# K1921VG7T register map
Vendor: NIIET; Series: K1921VKx; File version: 1.0
CPU: CM4 r0p1, Endian.LITTLE endian, MPU, FPU
Registers are 32-bit, read-write, reset 0x0 unless marked. A register's access mark holds for its fields unless they carry their own. Offsets are from the block's base; [hi:lo] are bit positions; lines under a group give offsets from that group; {n}, {i} and the like mark numbered series; 'fields as' and 'values as' point back to an identical list.

## RCU — Reset and clock unit
Base 0x50004000
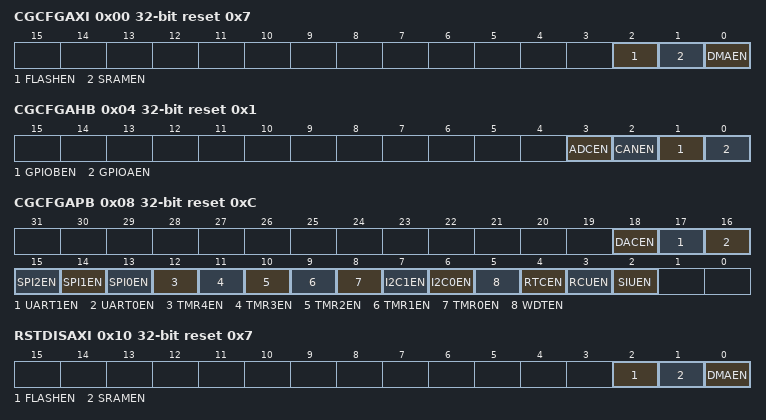
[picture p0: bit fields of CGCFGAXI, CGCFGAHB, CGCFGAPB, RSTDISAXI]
0x00 CGCFGAXI reset 0x7 — Clockgate Config AHB register
  [2] FLASHEN — Boot flash AXI and APB clock enable
  [1] SRAMEN — SRAM module clock enable
  [0] DMAEN — DMA AXI and APB clock enable
0x04 CGCFGAHB reset 0x1 — Clockgate Config AHB register
  [3] ADCEN, [2] CANEN, [1] GPIOBEN, [0] GPIOAEN
0x08 CGCFGAPB reset 0xC — Clockgate Config APB register
  [18] DACEN
  [17] UART1EN
  [16] UART0EN
  [15] SPI2EN
  [14] SPI1EN
  [13] SPI0EN
  [12] TMR4EN — TMR16_2 clock enable
  [11] TMR3EN — TMR16_1 clock enable
  [10] TMR2EN — TMR16_0 clock enable
  [9] TMR1EN — TMR32_1 clock enable
  [8] TMR0EN — TMR32_0 clock enable
  [7] I2C1EN
  [6] I2C0EN
  [5] WDTEN
  [4] RTCEN
  [3] RCUEN ro
  [2] SIUEN ro
0x10 RSTDISAXI reset 0x7 — Reset Disable AXI register
  [2] FLASHEN ro — Boot flash reset disable
  [1] SRAMEN — SRAM module reset disable
  [0] DMAEN — DMA reset disable
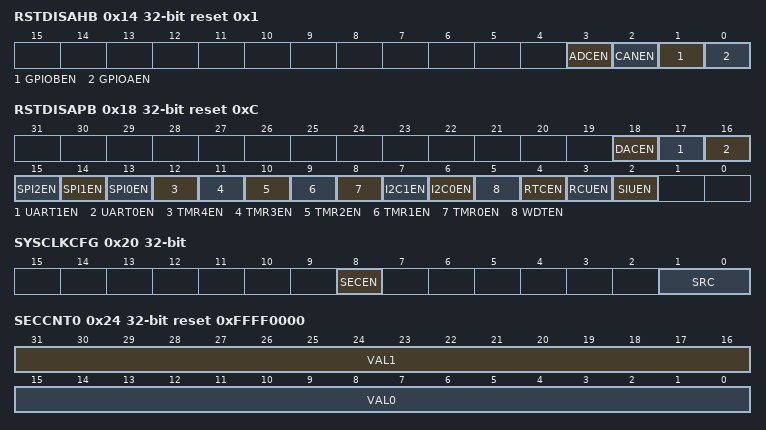
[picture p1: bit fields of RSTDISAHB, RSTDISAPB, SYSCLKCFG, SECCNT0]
0x14 RSTDISAHB reset 0x1 — Reset Disable AHB register
  [3] ADCEN, [2] CANEN, [1] GPIOBEN, [0] GPIOAEN
0x18 RSTDISAPB reset 0xC — Reset Disable APB register
  [18] DACEN
  [17] UART1EN
  [16] UART0EN
  [15] SPI2EN
  [14] SPI1EN
  [13] SPI0EN
  [12] TMR4EN — TMR16_2 clock enable
  [11] TMR3EN — TMR16_1 reset disable
  [10] TMR2EN — TMR16_0 reset disable
  [9] TMR1EN — TMR32_1 reset disable
  [8] TMR0EN — TMR32_0 reset disable
  [7] I2C1EN
  [6] I2C0EN
  [5] WDTEN
  [4] RTCEN
  [3] RCUEN ro
  [2] SIUEN ro
0x20 SYSCLKCFG — System clock configuration register
  [8] SECEN
  [1:0] SRC — System clock source
    0=REFCLK (HSI 1MHz if CPE=0 or HSE(XTALL) if CPE=1); 1=SRCCLK (HSE(XTALL) if CPE=0 or HSI 1MHz if CPE=1); 2=SYSPLL0CLK (Clock from PLL OUT[0]); 3=EXTCLK (external CLK from gpio pin)
0x24 SECCNT0 reset 0xFFFF0000 — Security counter configuration 0 register
  [31:16] VAL1, [15:0] VAL0 ro
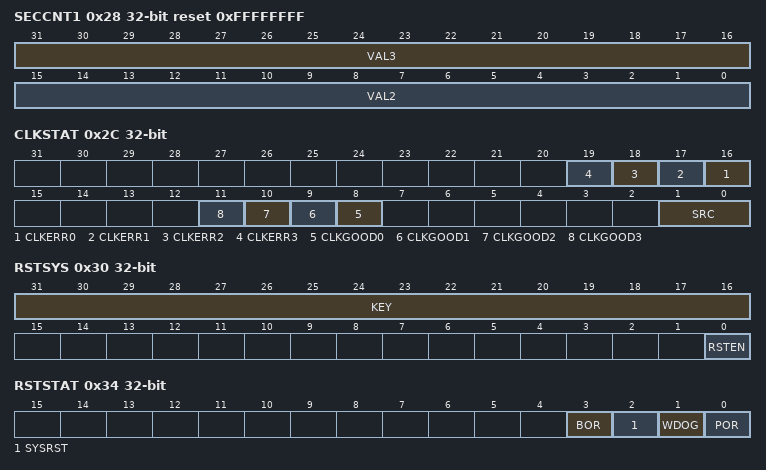
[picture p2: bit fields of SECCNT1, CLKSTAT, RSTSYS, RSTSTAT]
0x28 SECCNT1 reset 0xFFFFFFFF — Security counter configuration 1 register
  [31:16] VAL3, [15:0] VAL2
0x2C CLKSTAT ro — System clock status register
  [n+16] CLKERR{n} (n=0..3)
  [n+8] CLKGOOD{n} (n=0..3)
  [1:0] SRC — REFCLK:0:HSI 1MHz if CPE=0 or HSE(XTALL) if CPE=1;SRCCLK:1:HSE(XTALL) if CPE=0 or HSI 1MHz if CPE=1;SYSPLL0CLK:2: Clock from PLL OUT[0];EXTCLK:3: external CLK from gpio pin;
0x30 RSTSYS wo — System Reset Register
  [31:16] KEY — KEY 'A55A' in hexadecimal for unblocking
    0xA55A=VALID (Value that lead to chip reset if RSTEN = 1); 0=DUMMY_0 (Example value that prevents reset); 1=DUMMY_1 (Example value that prevents reset)
  [0] RSTEN — Reset enable
0x34 RSTSTAT — Reset Status Register
  [3] BOR — Brown-out reset status
  [2] SYSRST — System Reset Status
  [1] WDOG — WatchDog Reset status
  [0] POR — PowerOn Reset status
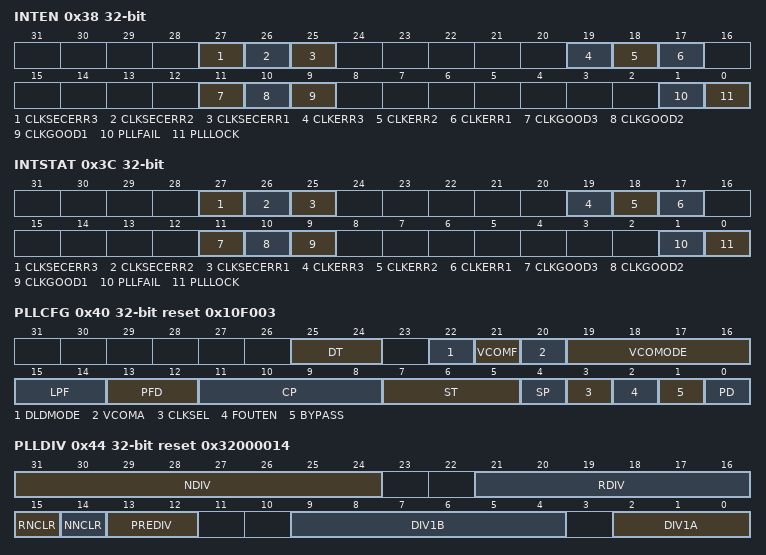
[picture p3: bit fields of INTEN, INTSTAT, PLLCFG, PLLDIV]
0x38 INTEN — Interrupt enable reigster
  [27] CLKSECERR3
  [26] CLKSECERR2
  [25] CLKSECERR1
  [19] CLKERR3
  [18] CLKERR2
  [17] CLKERR1
  [11] CLKGOOD3
  [10] CLKGOOD2
  [9] CLKGOOD1
  [1] PLLFAIL — Enable PLL fail to lock interrupt
  [0] PLLLOCK — Enable PLL lock interrupt
0x3C INTSTAT — Interrupt status register
  [27] CLKSECERR3
  [26] CLKSECERR2
  [25] CLKSECERR1
  [19] CLKERR3
  [18] CLKERR2
  [17] CLKERR1
  [11] CLKGOOD3
  [10] CLKGOOD2
  [9] CLKGOOD1
  [1] PLLFAIL — PLL lock signal drop occured
  [0] PLLLOCK — PLL lock signal raise occured
0x40 PLLCFG reset 0x10F003 — PLL Configuration Register
  [25:24] DT — fractional noise randomization mode
  [22] DLDMODE — Frequency detector delay
  [21] VCOMF — Ajust lower range of GUN
  [20] VCOMA — Ajust amplitude of GUN
  [19:16] VCOMODE — Subband selection signal
  [15:14] LPF — Loop filter band
  [13:12] PFD — Mode of current switch
  [11:8] CP — Output current of current switch
  [7:5] ST — Sggma-delta modulator mode
  [4] SP — Song-Park mode
  [3] CLKSEL — PLL reference clock source select
    0=HSE (external oscilator clock > 10 Mhz); 1=EXTCLK (external clock from GPIO pin)
  [2] FOUTEN — Fout enable
  [1] BYPASS — Bypass enable
  [0] PD — Powerdown enable
0x44 PLLDIV reset 0x32000014 — PLL DIV Configuration Register
  [31:24] NDIV — Integer part of divider (divide pre-divisor result by NDIV)
  [21:16] RDIV — R-divider coefficient (divide Fin by (RDIV + 1))
  [15] RNCLR — R-divider enable
  [14] NNCLR — N-divider enable
  [13:12] PREDIV — Pre-divisor coefficient. PREDIV = 0 | 1 | 2 | 3 -> divide Fvco by 1 | 1 | 2 | 3
  [9:4] DIV1B — Divider 1B (divide divider 1A result by (DIV1B + 1))
  [2:0] DIV1A — Divider 1A (divide pre-divisor result by (DIV1A + 1))
0x48 PLLFRAC — PLL FRAC Configuration Register
  [23:0] FRAC — numerator of fractional part
0x4C PLLMOD reset 0xFFFFFF — PLL MOD Configuration Register
  [23:0] MOD — denominator of fractional part
{0x50+4i} UARTCFG[{i}] (i=0..1) group
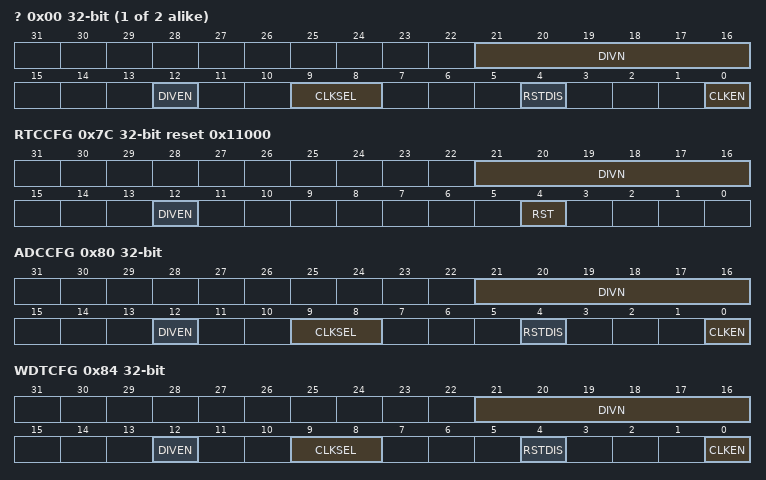
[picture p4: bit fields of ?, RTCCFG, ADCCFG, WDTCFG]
  0x00 ? — UART Clock and Reset Configuration Register
    [21:16] DIVN — Divider coefficient
    [12] DIVEN — Enable division by (2 * (DIVN + 1))
    [9:8] CLKSEL — Clock source select
      0=REFCLK (HSI 4MHz if CPE=0 or HSE(XTALL) if CPE=1); 1=SRCCLK (HSE(XTALL) if CPE=0 or HSI 4MHz if CPE=1); 2=SYSPLL0CLK (Clock from PLL OUT[0]); 3=EXTCLK (external CLK from gpio pin)
    [4] RSTDIS — Reset disable
    [0] CLKEN — Clock enable
{0x70+4i} SPICFG[{i}] (i=0..2) group
  0x00 ? — SPI Clock and Reset Configuration Register
    [21:16] DIVN — Divider coefficient
    [12] DIVEN — Enable divider by (2 * (DIVN + 1))
    [9:8] CLKSEL — Clock source select
      values as UARTCFG[0].?.CLKSEL
    [4] RSTDIS — Reset disable
    [0] CLKEN — Clock enable
0x7C RTCCFG reset 0x11000 — RTC APB clock divider and reset
  [21:16] DIVN — APB clock divider coefficient
  [12] DIVEN — Enable APB clock division by (2 * (DIVN + 1))
  [4] RST — Reset active High
0x80 ADCCFG — ADC Clock and Reset Configuration Register
  fields as UARTCFG[0].?
0x84 WDTCFG — WatchDog Configuration Register
  fields as UARTCFG[0].?
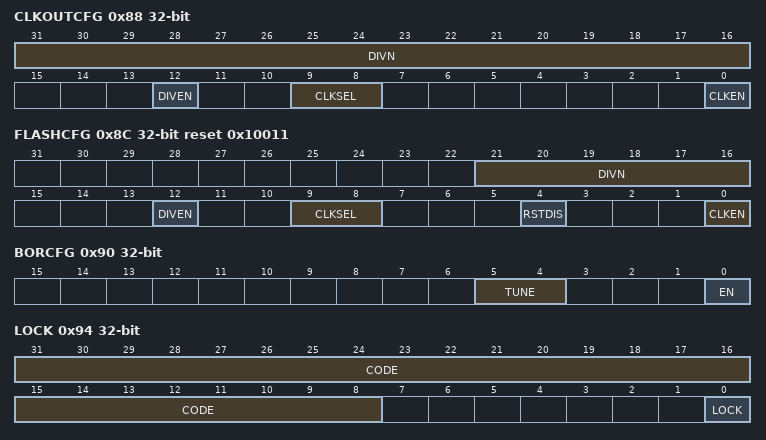
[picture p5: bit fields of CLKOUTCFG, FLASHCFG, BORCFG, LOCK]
0x88 CLKOUTCFG — Clockout Configuration Register
  [31:16] DIVN — Divider coefficient
  [12] DIVEN — Enable division by (2 * (DIVN + 1))
  [9:8] CLKSEL — Clock source select
    0=REFCLK (HSI 4MHz if CPE=0 or HSE(XTALL) if CPE=1); 1=SRCCLK (HSE(XTALL) if CPE=0 or HSI 4MHz if CPE=1); 2=SYSPLL0CLK (Clock from PLL OUT[0]); 3=LSI (32kHz oscilator)
  [0] CLKEN — Clock enable
0x8C FLASHCFG reset 0x10011 — Flash Configuration Register
  [21:16] DIVN — Divider coefficient
  [12] DIVEN — Enable division by (2 * (DIVN + 1))
  [9:8] CLKSEL ro — Clock source select
    values as UARTCFG[0].?.CLKSEL
  [4] RSTDIS ro — Reset disable
  [0] CLKEN — Clock enable
0x90 BORCFG — Brown-Out Reset Configuration Register
  [5:4] TUNE — Tune BOR level
  [0] EN — Enable BOR
0x94 LOCK — Lock configuration register
  [31:8] CODE wo — Write key 0xACCE55 to change LOCK bit value
    0xACCE55=CHANGE (Value that allows the LOCK bit to be changed); 0=DUMMY_0 (Example value that prevents the LOCK bit change); 1=DUMMY_1 (Example value that prevents the LOCK bit change)
  [0] LOCK — Write with specific code to lock / unlock writing to other RCU registers
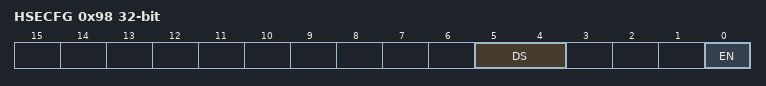
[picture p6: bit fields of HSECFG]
0x98 HSECFG — HSE Configuration Register
  [5:4] DS — Drive current select pins
  [0] EN — Enable HSE pins
